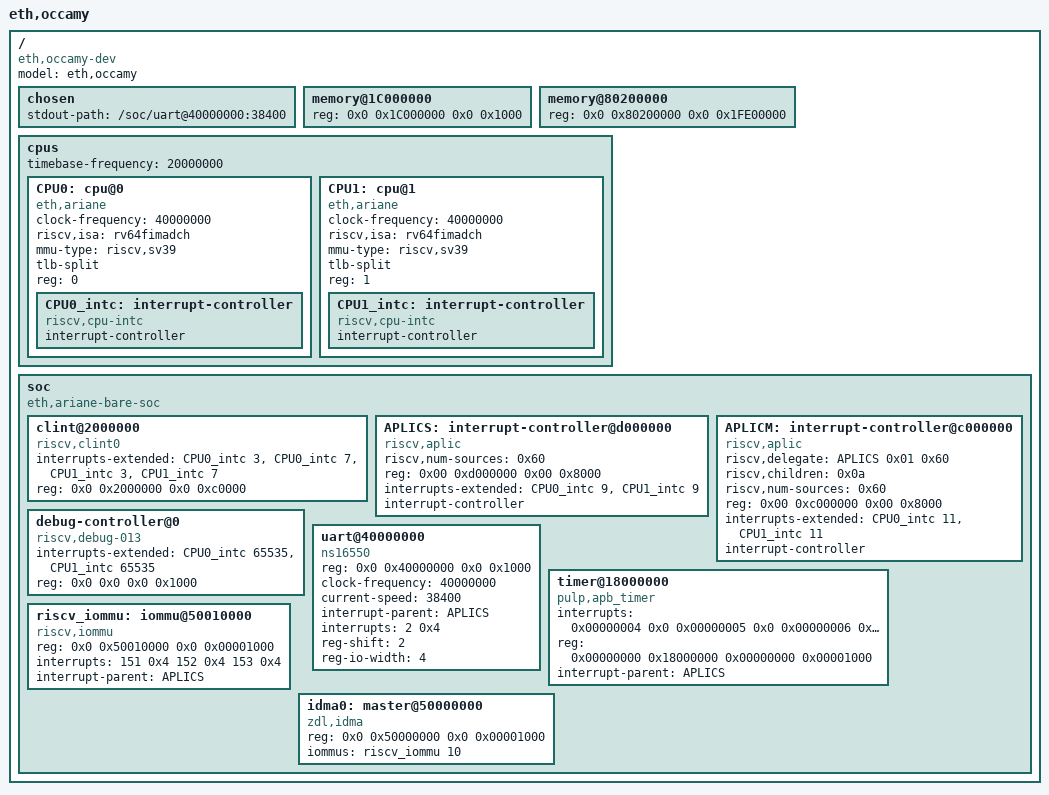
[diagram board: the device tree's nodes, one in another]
// Copyright 2021 ETH Zurich and University of Bologna.
// Licensed under the Apache License, Version 2.0, see LICENSE for details.
// SPDX-License-Identifier: Apache-2.0

// TODO(niwis) auto generate
/dts-v1/;
/ {
  #address-cells = <2>;
  #size-cells = <2>;
  compatible = "eth,occamy-dev";
  model = "eth,occamy";
  chosen {
    stdout-path = "/soc/uart@40000000:38400";
  };
  memory@1C000000 {
    device_type = "memory";
    reg = <0x0 0x1C000000 0x0 0x1000>;
  };
  memory@80200000 {
    device_type = "memory";
    reg = <0x0 0x80200000 0x0 0x1FE00000>;
  };
  cpus {
    #address-cells = <1>;
    #size-cells = <0>;
    timebase-frequency = <20000000>;
    CPU0: cpu@0 {
      device_type = "cpu";
      status = "okay";
      compatible = "eth,ariane", "riscv";
      clock-frequency = <40000000>;
      riscv,isa = "rv64fimadch";
      mmu-type = "riscv,sv39";
      tlb-split;
      reg = <0>;
      CPU0_intc: interrupt-controller {
        #address-cells = <1>;
        #interrupt-cells = <1>;
        interrupt-controller;
        compatible = "riscv,cpu-intc";
      };
    };
    CPU1: cpu@1 {
      device_type = "cpu";
      status = "okay";
      compatible = "eth,ariane", "riscv";
      clock-frequency = <40000000>;
      riscv,isa = "rv64fimadch";
      mmu-type = "riscv,sv39";
      tlb-split;
      reg = <1>;
      CPU1_intc: interrupt-controller {
        #address-cells = <1>;
        #interrupt-cells = <1>;
        interrupt-controller;
        compatible = "riscv,cpu-intc";
      };
    };

  };
  soc: soc {
    #address-cells = <2>;
    #size-cells = <2>;
    compatible = "eth,ariane-bare-soc", "simple-bus";
    ranges;
    clint@2000000 {
      compatible = "riscv,clint0";
      interrupts-extended = <&CPU0_intc 3 &CPU0_intc 7>  , <&CPU1_intc 3 &CPU1_intc 7>;
      reg = <0x0 0x2000000 0x0 0xc0000>;
      reg-names = "control";
    };
    APLICS: interrupt-controller@d000000 {
      phandle = <0x0a>;
      riscv,num-sources = <0x60>;
      reg = <0x00 0xd000000 0x00 0x8000>;
      interrupts-extended = <&CPU0_intc 9>  , <&CPU1_intc 9>;
      interrupt-controller;
      #interrupt-cells = <0x02>;
      compatible = "riscv,aplic";
    };

     APLICM: interrupt-controller@c000000 {
       phandle = <0x09>;
       riscv,delegate = <&APLICS 0x01 0x60>;
       riscv,children = <0x0a>;
       riscv,num-sources = <0x60>;
       reg = <0x00 0xc000000 0x00 0x8000>;
       interrupts-extended = <&CPU0_intc 11>, <&CPU1_intc 11>;
       interrupt-controller;
       #interrupt-cells = <0x02>;
       compatible = "riscv,aplic";
     };

    debug-controller@0 {
      compatible = "riscv,debug-013";
      interrupts-extended = <&CPU0_intc 65535>  , <&CPU1_intc 65535>;
      reg = <0x0 0x0 0x0 0x1000>;
      reg-names = "control";
    };
    uart@40000000 {
      compatible = "ns16550";
      reg = <0x0 0x40000000 0x0 0x1000>;
      clock-frequency = <40000000>;
      current-speed = <38400>;
      interrupt-parent = <&APLICS>;
      interrupts = <2 0x4>;
      reg-shift = <2>; // regs are spaced on 32 bit boundary
      reg-io-width = <4>; // only 32-bit access are supported
    };
    timer@18000000 {
      compatible = "pulp,apb_timer";
      interrupts = <0x00000004 0x0 0x00000005 0x0 0x00000006 0x0 0x00000007 0x0>;
      reg = <0x00000000 0x18000000 0x00000000 0x00001000>;
      interrupt-parent = <&APLICS>;
      reg-names = "control";
    };
    riscv_iommu: iommu@50010000 {
      compatible = "riscv,iommu";
      reg = <0x0 0x50010000 0x0 0x00001000>;
      interrupts = <151 0x4 152 0x4 153 0x4>;
      interrupt-names = "cmdq", "fltq", "hpm";
      interrupt-parent = <&APLICS>;
      #iommu-cells = <1>;
    };
    idma0: master@50000000{
      compatible = "zdl,idma";
      reg = <0x0 0x50000000 0x0 0x00001000>;
      iommus = <&riscv_iommu 10>;
    };
  };
};
